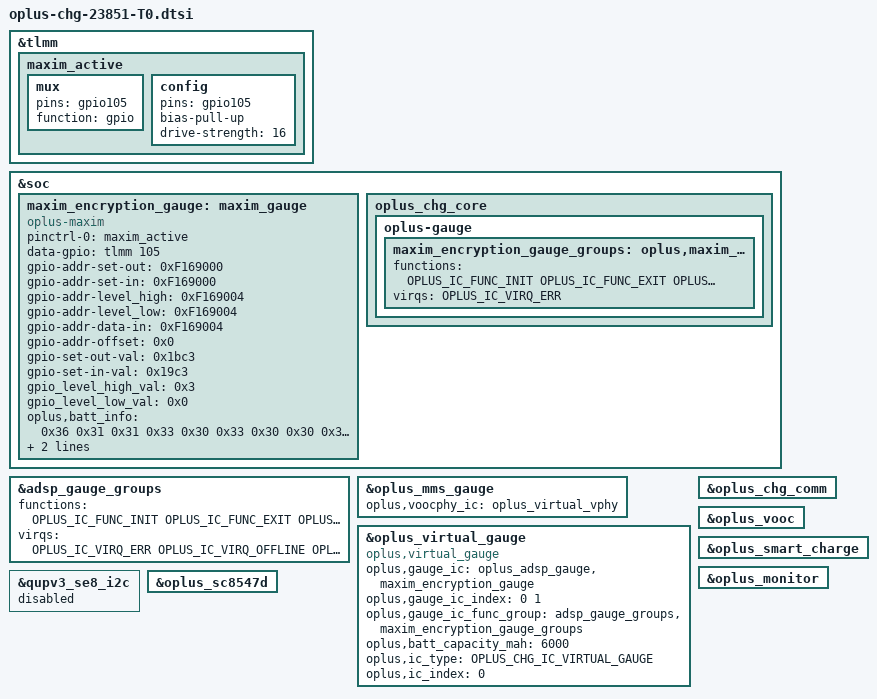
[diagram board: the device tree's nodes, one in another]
#include "oplus-chg-23851.dtsi"

&tlmm {
	maxim_active: maxim_active {
		mux {
			pins = "gpio105";
			function = "gpio";
		};

		config {
			pins = "gpio105";
			bias-pull-up;
			drive-strength = <16>;
		};
	};
};

&soc {
	maxim_encryption_gauge: maxim_gauge {
		status = "ok";
		compatible = "oplus-maxim";
		pinctrl-names = "maxim_active";
		pinctrl-0 = <&maxim_active>;
		data-gpio = <&tlmm 105 0x00>;
		gpio-addr-set-out = <0xF169000>;
		gpio-addr-set-in = <0xF169000>;
		gpio-addr-level_high = <0xF169004>;
		gpio-addr-level_low = <0xF169004>;
		gpio-addr-data-in = <0xF169004>;
		gpio-addr-offset = <0x0>;

		gpio-set-out-val = <0x1bc3>;
		gpio-set-in-val = <0x19c3>;
		gpio_level_high_val = <0x3>;
		gpio_level_low_val = <0x0>;

		oplus,batt_info = /bits/ 8 <0x36 0x31 0x31 0x33 0x30 0x33 0x30 0x30 0x30 0x31 0x31 0x39   /* 611303000119 */
					    0x36 0x31 0x31 0x33 0x30 0x33 0x30 0x30 0x30 0x31 0x32 0x30   /* 611303000120 */
					    0x36 0x31 0x31 0x33 0x30 0x33 0x30 0x30 0x30 0x30 0x36 0x33>; /* 611303000063 S2 SN */

		oplus,ic_type = <OPLUS_CHG_IC_GAUGE>;
		oplus,ic_index = <1>;
	};

	oplus_chg_core {
		oplus-gauge {
			maxim_encryption_gauge_groups: oplus,maxim_encryption_gauge_groups {
				functions = <
					OPLUS_IC_FUNC_INIT
					OPLUS_IC_FUNC_EXIT
					OPLUS_IC_FUNC_GAUGE_GET_BATT_AUTH
				>;
				virqs = <
					OPLUS_IC_VIRQ_ERR
				>;
			};
		};
	};
};

&adsp_gauge_groups {
	functions = <
		OPLUS_IC_FUNC_INIT
		OPLUS_IC_FUNC_EXIT
		OPLUS_IC_FUNC_REG_DUMP
		OPLUS_IC_FUNC_SMT_TEST
		OPLUS_IC_FUNC_GAUGE_GET_BATT_VOL
		OPLUS_IC_FUNC_GAUGE_GET_BATT_MAX
		OPLUS_IC_FUNC_GAUGE_GET_BATT_MIN
		OPLUS_IC_FUNC_GAUGE_GET_BATT_CURR
		OPLUS_IC_FUNC_GAUGE_GET_BATT_TEMP
		OPLUS_IC_FUNC_GAUGE_GET_BATT_SOC
		OPLUS_IC_FUNC_GAUGE_GET_BATT_FCC
		OPLUS_IC_FUNC_GAUGE_GET_BATT_CC
		OPLUS_IC_FUNC_GAUGE_GET_BATT_RM
		OPLUS_IC_FUNC_GAUGE_GET_BATT_SOH
		OPLUS_IC_FUNC_GAUGE_GET_BATT_HMAC
		OPLUS_IC_FUNC_GAUGE_SET_BATT_FULL
		OPLUS_IC_FUNC_GAUGE_UPDATE_DOD0
		OPLUS_IC_FUNC_GAUGE_UPDATE_SOC_SMOOTH
		OPLUS_IC_FUNC_GAUGE_GET_CB_STATUS
		OPLUS_IC_FUNC_GAUGE_GET_BATT_NUM
		OPLUS_IC_FUNC_GAUGE_GET_DEVICE_TYPE
		OPLUS_IC_FUNC_GAUGE_GET_DEVICE_TYPE_FOR_VOOC
		OPLUS_IC_FUNC_GAUGE_GET_BATT_FCC
		OPLUS_IC_FUNC_GAUGE_UPDATE
		OPLUS_IC_FUNC_GAUGE_IS_SUSPEND
		OPLUS_IC_FUNC_GAUGE_GET_SUBBOARD_TEMP
		OPLUS_IC_FUNC_GAUGE_GET_BCC_PARMS
		OPLUS_IC_FUNC_GAUGE_GET_DEVICE_TYPE_FOR_BCC
		OPLUS_IC_FUNC_GAUGE_GET_DOD0
		OPLUS_IC_FUNC_GAUGE_GET_DOD0_PASSED_Q
		OPLUS_IC_FUNC_GAUGE_GET_QMAX
		OPLUS_IC_FUNC_GAUGE_GET_QMAX_PASSED_Q
	>;
	virqs = <
		OPLUS_IC_VIRQ_ERR
		OPLUS_IC_VIRQ_OFFLINE
		OPLUS_IC_VIRQ_RESUME
	>;
};

&oplus_mms_gauge {
	oplus,voocphy_ic = <&oplus_virtual_vphy>;
};

&oplus_virtual_gauge {
	compatible = "oplus,virtual_gauge";
	oplus,gauge_ic = <&oplus_adsp_gauge &maxim_encryption_gauge>;
	oplus,gauge_ic_index = <0 1>;
	oplus,gauge_ic_func_group = <&adsp_gauge_groups &maxim_encryption_gauge_groups>;
	oplus,batt_capacity_mah = <6000>;
	oplus,ic_type = <OPLUS_CHG_IC_VIRTUAL_GAUGE>;
	oplus,ic_index = <0>;
};

&oplus_chg_comm {
	/delete-property/ oplus_spec,wired-aging-ffc-version;
	/delete-property/ oplus_spec,wired-aging-ffc-offset-mv;
	/delete-property/ oplus_spec,wired-aging-ffc-cycle-thr;

	/delete-property/ oplus,smooth_switch;
	/delete-property/ oplus,reserve_chg_soc;
	/delete-property/ oplus,reserve_dis_soc;
};

&oplus_vooc {
	/delete-property/ oplus,smart_chg_bcc_support;
};

&oplus_smart_charge {
	/delete-property/ oplus,smart_chg_soh_support;
};

&oplus_monitor {
	/delete-property/ track,gauge_status_ctrl;
	/delete-property/ track,nominal_qmax1;
	/delete-property/ track,nominal_fcc1;
	/delete-property/ track,external_gauge_num;

	/delete-property/ track,gauge_max_cell_vol;
	/delete-property/ track,gauge_max_charge_curr;
	/delete-property/ track,gauge_max_dischg_curr;
	/delete-property/ track,gauge_min_cell_temp;
	/delete-property/ track,gauge_max_cell_temp;
	/delete-property/ track,gauge_lifetime_support;
};

&qupv3_se8_i2c {
	status = "disabled";
};

/delete-node/ &bq27541_groups;
/delete-node/ &oplus_ext_gauge;

&oplus_sc8547d {
	/delete-property/ oplus_spec,external_gauge_support;
};
